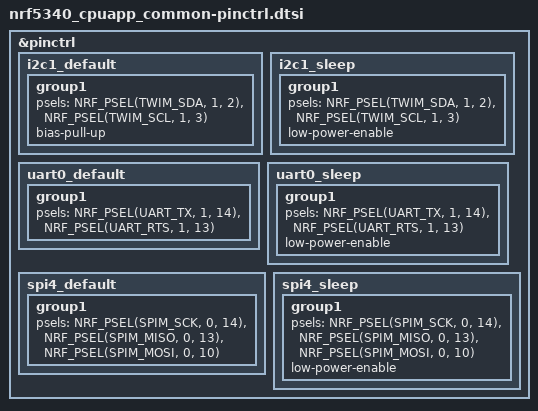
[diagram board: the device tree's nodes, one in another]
/*
 * Copyright (c) 2022 Nordic Semiconductor
 * SPDX-License-Identifier: Apache-2.0
 */

&pinctrl {
	i2c1_default: i2c1_default {
		group1 {
			psels = <NRF_PSEL(TWIM_SDA, 1, 2)>,
			    	<NRF_PSEL(TWIM_SCL, 1, 3)>;
            bias-pull-up;
		};
	};

	i2c1_sleep: i2c1_sleep {
		group1 {
			psels = <NRF_PSEL(TWIM_SDA, 1, 2)>,
		    		<NRF_PSEL(TWIM_SCL, 1, 3)>;
			low-power-enable;
		};
	};

	uart0_default: uart0_default {
		group1 {
			psels = <NRF_PSEL(UART_TX, 1, 14)>,
				    <NRF_PSEL(UART_RTS, 1, 13)>;
		};
	};

	uart0_sleep: uart0_sleep {
		group1 {
			psels = <NRF_PSEL(UART_TX, 1, 14)>,
				    <NRF_PSEL(UART_RTS, 1, 13)>;
			low-power-enable;
		};
	};

	spi4_default: spi4_default {
		group1 {
			psels = <NRF_PSEL(SPIM_SCK, 0, 14)>,
			    	<NRF_PSEL(SPIM_MISO, 0, 13)>,
			    	<NRF_PSEL(SPIM_MOSI, 0, 10)>;
		};
	};

	spi4_sleep: spi4_sleep {
		group1 {
			psels = <NRF_PSEL(SPIM_SCK, 0, 14)>,
			    	<NRF_PSEL(SPIM_MISO, 0, 13)>,
			    	<NRF_PSEL(SPIM_MOSI, 0, 10)>;
			low-power-enable;
		};
	};
};
